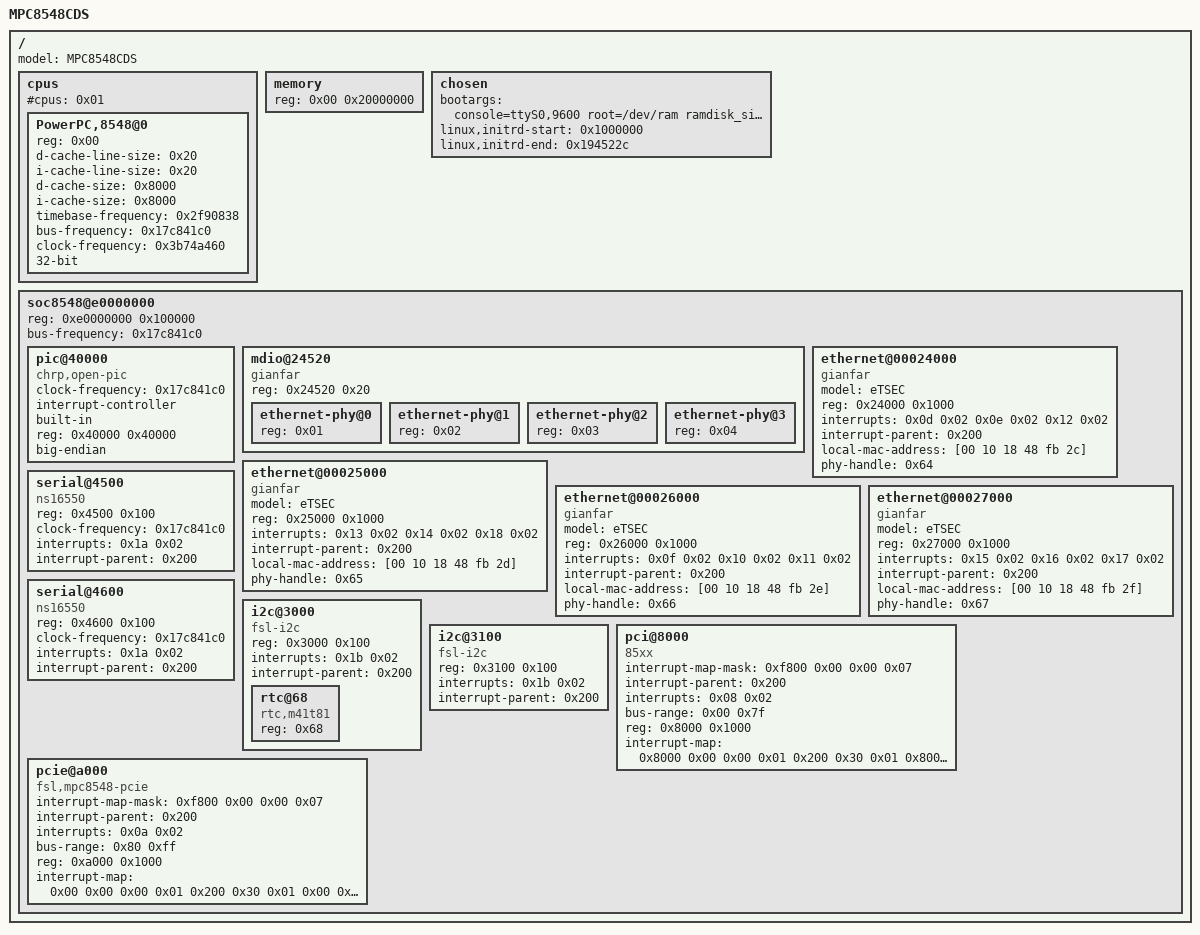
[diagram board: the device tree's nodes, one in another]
/dts-v1/;

/memreserve/	0x1ff8f44000004000 0x010000000094522c;
/ {
	model = "MPC8548CDS";
	#address-cells = <0x01>;
	#size-cells = <0x01>;

	cpus {
		#cpus = <0x01>;
		#address-cells = <0x01>;
		#size-cells = <0x00>;

		PowerPC,8548@0 {
			device_type = "cpu";
			reg = <0x00>;
			d-cache-line-size = <0x20>;
			i-cache-line-size = <0x20>;
			d-cache-size = <0x8000>;
			i-cache-size = <0x8000>;
			timebase-frequency = <0x2f90838>;
			bus-frequency = <0x17c841c0>;
			clock-frequency = <0x3b74a460>;
			32-bit;
		};
	};

	memory {
		device_type = "memory";
		reg = <0x00 0x20000000>;
	};

	chosen {
		bootargs = "console=ttyS0,9600 root=/dev/ram ramdisk_size=65536 rd_start=0x1000000 rd_size=9720364 rdinit=/bin/sh";
		linux,initrd-start = <0x1000000>;
		linux,initrd-end = <0x194522c>;
	};

	soc8548@e0000000 {
		#address-cells = <0x01>;
		#size-cells = <0x01>;
		#interrupt-cells = <0x02>;
		device_type = "soc";
		ranges = <0x00 0xe0000000 0x100000>;
		reg = <0xe0000000 0x100000>;
		bus-frequency = <0x17c841c0>;

		pic@40000 {
			linux,phandle = <0x200>;
			clock-frequency = <0x17c841c0>;
			interrupt-controller;
			built-in;
			#address-cells = <0x00>;
			#interrupt-cells = <0x02>;
			reg = <0x40000 0x40000>;
			device_type = "open-pic";
			compatible = "chrp,open-pic";
			big-endian;
		};

		mdio@24520 {
			#address-cells = <0x01>;
			#size-cells = <0x00>;
			device_type = "mdio";
			compatible = "gianfar";
			reg = <0x24520 0x20>;

			ethernet-phy@0 {
				device_type = "ethernet-phy";
				reg = <0x01>;
				linux,phandle = <0x64>;
			};

			ethernet-phy@1 {
				device_type = "ethernet-phy";
				reg = <0x02>;
				linux,phandle = <0x65>;
			};

			ethernet-phy@2 {
				device_type = "ethernet-phy";
				reg = <0x03>;
				linux,phandle = <0x66>;
			};

			ethernet-phy@3 {
				device_type = "ethernet-phy";
				reg = <0x04>;
				linux,phandle = <0x67>;
			};
		};

		ethernet@00024000 {
			#address-cells = <0x01>;
			#size-cells = <0x00>;
			device_type = "network";
			model = "eTSEC";
			compatible = "gianfar";
			reg = <0x24000 0x1000>;
			interrupts = <0x0d 0x02 0x0e 0x02 0x12 0x02>;
			interrupt-parent = <0x200>;
			local-mac-address = [00 10 18 48 fb 2c];
			phy-handle = <0x64>;
		};

		ethernet@00025000 {
			#address-cells = <0x01>;
			#size-cells = <0x00>;
			device_type = "network";
			model = "eTSEC";
			compatible = "gianfar";
			reg = <0x25000 0x1000>;
			interrupts = <0x13 0x02 0x14 0x02 0x18 0x02>;
			interrupt-parent = <0x200>;
			local-mac-address = [00 10 18 48 fb 2d];
			phy-handle = <0x65>;
		};

		ethernet@00026000 {
			#address-cells = <0x01>;
			#size-cells = <0x00>;
			device_type = "network";
			model = "eTSEC";
			compatible = "gianfar";
			reg = <0x26000 0x1000>;
			interrupts = <0x0f 0x02 0x10 0x02 0x11 0x02>;
			interrupt-parent = <0x200>;
			local-mac-address = [00 10 18 48 fb 2e];
			phy-handle = <0x66>;
		};

		ethernet@00027000 {
			#address-cells = <0x01>;
			#size-cells = <0x00>;
			device_type = "network";
			model = "eTSEC";
			compatible = "gianfar";
			reg = <0x27000 0x1000>;
			interrupts = <0x15 0x02 0x16 0x02 0x17 0x02>;
			interrupt-parent = <0x200>;
			local-mac-address = [00 10 18 48 fb 2f];
			phy-handle = <0x67>;
		};

		serial@4500 {
			device_type = "serial";
			compatible = "ns16550";
			reg = <0x4500 0x100>;
			clock-frequency = <0x17c841c0>;
			interrupts = <0x1a 0x02>;
			interrupt-parent = <0x200>;
		};

		serial@4600 {
			device_type = "serial";
			compatible = "ns16550";
			reg = <0x4600 0x100>;
			clock-frequency = <0x17c841c0>;
			interrupts = <0x1a 0x02>;
			interrupt-parent = <0x200>;
		};

		i2c@3000 {
			device_type = "i2c";
			compatible = "fsl-i2c";
			reg = <0x3000 0x100>;
			interrupts = <0x1b 0x02>;
			interrupt-parent = <0x200>;

			rtc@68 {
				compatible = "rtc,m41t81";
				reg = <0x68>;
			};
		};

		i2c@3100 {
			device_type = "i2c";
			compatible = "fsl-i2c";
			reg = <0x3100 0x100>;
			interrupts = <0x1b 0x02>;
			interrupt-parent = <0x200>;
		};

		pci@8000 {
			interrupt-map-mask = <0xf800 0x00 0x00 0x07>;
			interrupt-parent = <0x200>;
			interrupts = <0x08 0x02>;
			bus-range = <0x00 0x7f>;
			ranges = <0x2000000 0x00 0x50000000 0x50000000 0x00 0x10000000 0x1000000 0x00 0x00 0xe2000000 0x00 0x4000000>;
			#interrupt-cells = <0x01>;
			#size-cells = <0x02>;
			#address-cells = <0x03>;
			reg = <0x8000 0x1000>;
			compatible = "85xx";
			device_type = "pci";
			linux,phandle = <0x300>;
			interrupt-map = <0x8000 0x00 0x00 0x01 0x200 0x30 0x01 0x8000 0x00 0x00 0x02 0x200 0x30 0x01 0x8000 0x00 0x00 0x03 0x200 0x30 0x01 0x8000 0x00 0x00 0x04 0x200 0x30 0x01 0x8800 0x00 0x00 0x01 0x200 0x30 0x01 0x8800 0x00 0x00 0x02 0x200 0x30 0x01 0x8800 0x00 0x00 0x03 0x200 0x30 0x01 0x8800 0x00 0x00 0x04 0x200 0x30 0x01 0x9000 0x00 0x00 0x01 0x200 0x30 0x01 0x9000 0x00 0x00 0x02 0x200 0x30 0x01 0x9000 0x00 0x00 0x03 0x200 0x30 0x01 0x9000 0x00 0x00 0x04 0x200 0x30 0x01 0x9800 0x00 0x00 0x01 0x200 0x30 0x01 0x9800 0x00 0x00 0x02 0x200 0x30 0x01 0x9800 0x00 0x00 0x03 0x200 0x30 0x01 0x9800 0x00 0x00 0x04 0x200 0x30 0x01 0xa000 0x00 0x00 0x01 0x200 0x30 0x01 0xa000 0x00 0x00 0x02 0x200 0x30 0x01 0xa000 0x00 0x00 0x03 0x200 0x30 0x01 0xa000 0x00 0x00 0x04 0x200 0x30 0x01 0xa800 0x00 0x00 0x01 0x200 0x30 0x01 0xa800 0x00 0x00 0x02 0x200 0x30 0x01 0xa800 0x00 0x00 0x03 0x200 0x30 0x01 0xa800 0x00 0x00 0x04 0x200 0x30 0x01 0xb000 0x00 0x00 0x01 0x200 0x30 0x01 0xb000 0x00 0x00 0x02 0x200 0x30 0x01 0xb000 0x00 0x00 0x03 0x200 0x30 0x01 0xb000 0x00 0x00 0x04 0x200 0x30 0x01 0xb800 0x00 0x00 0x01 0x200 0x30 0x01 0xb800 0x00 0x00 0x02 0x200 0x30 0x01 0xb800 0x00 0x00 0x03 0x200 0x30 0x01 0xb800 0x00 0x00 0x04 0x200 0x30 0x01 0xc000 0x00 0x00 0x01 0x200 0x30 0x01 0xc000 0x00 0x00 0x02 0x200 0x30 0x01 0xc000 0x00 0x00 0x03 0x200 0x30 0x01 0xc000 0x00 0x00 0x04 0x200 0x30 0x01 0xc800 0x00 0x00 0x01 0x200 0x30 0x01 0xc800 0x00 0x00 0x02 0x200 0x30 0x01 0xc800 0x00 0x00 0x03 0x200 0x30 0x01 0xc800 0x00 0x00 0x04 0x200 0x30 0x01 0xd000 0x00 0x00 0x01 0x200 0x30 0x01 0xd000 0x00 0x00 0x02 0x200 0x30 0x01 0xd000 0x00 0x00 0x03 0x200 0x30 0x01 0xd000 0x00 0x00 0x04 0x200 0x30 0x01 0xd800 0x00 0x00 0x01 0x200 0x30 0x01 0xd800 0x00 0x00 0x02 0x200 0x30 0x01 0xd800 0x00 0x00 0x03 0x200 0x30 0x01 0xd800 0x00 0x00 0x04 0x200 0x30 0x01 0xe000 0x00 0x00 0x01 0x200 0x30 0x01 0xe000 0x00 0x00 0x02 0x200 0x30 0x01 0xe000 0x00 0x00 0x03 0x200 0x30 0x01 0xe000 0x00 0x00 0x04 0x200 0x30 0x01 0xe800 0x00 0x00 0x01 0x200 0x30 0x01 0xe800 0x00 0x00 0x02 0x200 0x30 0x01 0xe800 0x00 0x00 0x03 0x200 0x30 0x01 0xe800 0x00 0x00 0x04 0x200 0x30 0x01 0xf000 0x00 0x00 0x01 0x200 0x30 0x01 0xf000 0x00 0x00 0x02 0x200 0x30 0x01 0xf000 0x00 0x00 0x03 0x200 0x30 0x01 0xf000 0x00 0x00 0x04 0x200 0x30 0x01 0xf800 0x00 0x00 0x01 0x200 0x30 0x01 0xf800 0x00 0x00 0x02 0x200 0x30 0x01 0xf800 0x00 0x00 0x03 0x200 0x30 0x01 0xf800 0x00 0x00 0x04 0x200 0x30 0x01>;
		};

		pcie@a000 {
			interrupt-map-mask = <0xf800 0x00 0x00 0x07>;
			interrupt-parent = <0x200>;
			interrupts = <0x0a 0x02>;
			bus-range = <0x80 0xff>;
			ranges = <0x2000000 0x00 0x60000000 0x60000000 0x00 0x10000000 0x1000000 0x00 0x00 0xe8000000 0x00 0x4000000>;
			#interrupt-cells = <0x01>;
			#size-cells = <0x02>;
			#address-cells = <0x03>;
			reg = <0xa000 0x1000>;
			compatible = "fsl,mpc8548-pcie";
			device_type = "pci";
			interrupt-map = <0x00 0x00 0x00 0x01 0x200 0x30 0x01 0x00 0x00 0x00 0x02 0x200 0x30 0x01 0x00 0x00 0x00 0x03 0x200 0x30 0x01 0x00 0x00 0x00 0x04 0x200 0x30 0x01 0x800 0x00 0x00 0x01 0x200 0x31 0x01 0x800 0x00 0x00 0x02 0x200 0x31 0x01 0x800 0x00 0x00 0x03 0x200 0x31 0x01 0x800 0x00 0x00 0x04 0x200 0x31 0x01 0x1000 0x00 0x00 0x01 0x200 0x12f 0x01 0x1000 0x00 0x00 0x02 0x200 0x12f 0x01 0x1000 0x00 0x00 0x03 0x200 0x12f 0x01 0x1000 0x00 0x00 0x04 0x200 0x12f 0x01 0x1800 0x00 0x00 0x01 0x200 0x12f 0x01 0x1800 0x00 0x00 0x02 0x200 0x12f 0x01 0x1800 0x00 0x00 0x03 0x200 0x12f 0x01 0x1800 0x00 0x00 0x04 0x200 0x12f 0x01 0x2000 0x00 0x00 0x01 0x200 0x30 0x01 0x2000 0x00 0x00 0x02 0x200 0x30 0x01 0x2000 0x00 0x00 0x03 0x200 0x30 0x01 0x2000 0x00 0x00 0x04 0x200 0x30 0x01 0x2800 0x00 0x00 0x01 0x200 0x31 0x01 0x2800 0x00 0x00 0x02 0x200 0x31 0x01 0x2800 0x00 0x00 0x03 0x200 0x31 0x01 0x2800 0x00 0x00 0x04 0x200 0x31 0x01 0x3000 0x00 0x00 0x01 0x200 0x32 0x01 0x3000 0x00 0x00 0x02 0x200 0x32 0x01 0x3000 0x00 0x00 0x03 0x200 0x32 0x01 0x3000 0x00 0x00 0x04 0x200 0x32 0x01 0x3800 0x00 0x00 0x01 0x200 0x33 0x01 0x3800 0x00 0x00 0x02 0x200 0x33 0x01 0x3800 0x00 0x00 0x03 0x200 0x33 0x01 0x3800 0x00 0x00 0x04 0x200 0x33 0x01 0x4000 0x00 0x00 0x01 0x200 0x30 0x01 0x4000 0x00 0x00 0x02 0x200 0x30 0x01 0x4000 0x00 0x00 0x03 0x200 0x30 0x01 0x4000 0x00 0x00 0x04 0x200 0x30 0x01 0x4800 0x00 0x00 0x01 0x200 0x31 0x01 0x4800 0x00 0x00 0x02 0x200 0x31 0x01 0x4800 0x00 0x00 0x03 0x200 0x31 0x01 0x4800 0x00 0x00 0x04 0x200 0x31 0x01 0x5000 0x00 0x00 0x01 0x200 0x12f 0x01 0x5000 0x00 0x00 0x02 0x200 0x12f 0x01 0x5000 0x00 0x00 0x03 0x200 0x12f 0x01 0x5000 0x00 0x00 0x04 0x200 0x12f 0x01 0x5800 0x00 0x00 0x01 0x200 0x12f 0x01 0x5800 0x00 0x00 0x02 0x200 0x12f 0x01 0x5800 0x00 0x00 0x03 0x200 0x12f 0x01 0x5800 0x00 0x00 0x04 0x200 0x12f 0x01>;
		};
	};
};
